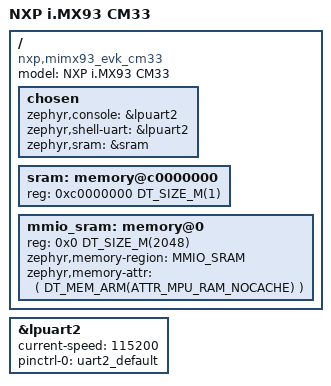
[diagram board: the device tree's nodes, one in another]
/*
 * Copyright 2024 NXP
 *
 * SPDX-License-Identifier: Apache-2.0
 */

/dts-v1/;

#include <nxp/nxp_mimx93_cm33.dtsi>
#include <zephyr/dt-bindings/memory-attr/memory-attr-arm.h>

#include "mimx93_evk-pinctrl.dtsi"

/ {
	model = "NXP i.MX93 CM33";
	compatible = "nxp,mimx93_evk_cm33";

	chosen {
		zephyr,console = &lpuart2;
		zephyr,shell-uart = &lpuart2;
		zephyr,sram = &sram;
	};

	sram: memory@c0000000 {
		reg = <0xc0000000 DT_SIZE_M(1)>;
	};

	mmio_sram: memory@0 {
		reg = <0x0 DT_SIZE_M(2048)>;
		zephyr,memory-region = "MMIO_SRAM";
		zephyr,memory-attr = <( DT_MEM_ARM(ATTR_MPU_RAM_NOCACHE) )>;
	};
};

&lpuart2 {
	status = "okay";
	current-speed = <115200>;
	pinctrl-0 = <&uart2_default>;
	pinctrl-names = "default";
};
